# cyw20829 register map
Vendor: Infineon Technologies; Series: CYW20829; File version: 1.0
CPU: CM33 r0p1, little endian, MPU, no FPU, VTOR, 3 interrupt priority bits
Registers are 32-bit, read-write, reset 0x0 unless marked. A register's access mark holds for its fields unless they carry their own. Offsets are from the block's base; [hi:lo] are bit positions; {n}, {i} and the like mark numbered series.

## MXS40ADCMIC0 — ADC
Base 0x40520000
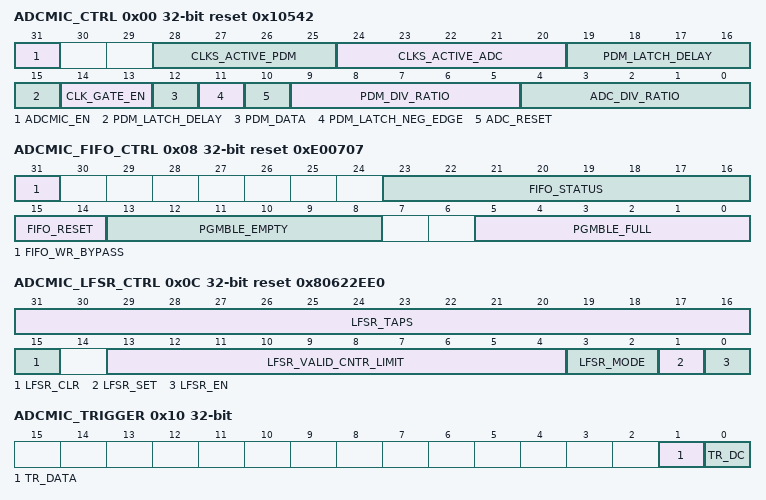
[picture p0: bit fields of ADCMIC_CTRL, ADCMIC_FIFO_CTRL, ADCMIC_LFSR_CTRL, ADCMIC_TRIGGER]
0x00 ADCMIC_CTRL reset 0x10542 — Control the operation of the ADCMIC block including clock generation,clock selection and pdm data latching
  [31] ADCMIC_EN — Enables the adcmic operation This bit controls the pdm data being latched to begin the adcmic operation.
  [28:25] CLKS_ACTIVE_PDM — clk sel for clk_pdm - one hot encoded but the lower 2 bits and the upper 2 bits are independent of each other 0000 : No clocks selected - clock is gated off XX01 : clk_pdm from local clk_divder is selected for external clk_pdm XX10 : Inverted clk_pdm from local clk_divder is selected for external clk_pdm 01XX : clk_pdm from local clk_divder is selected as internal clk_adc to process pdm_data 10XX : Inverted clk_pdm from local clk_divder is selected as internal clk_adc to latch pdm_data
  [24:20] CLKS_ACTIVE_ADC — clk sel for clk_adc - one hot encoded 00000 : No clocks selected - clock is gated off 00001 : clk_adc from local clk_divder is selected 00010 : Inverted clk_adc from local clk_divder is selected 00100 : clk_adc received from adc is used 01000 : Inverted clk_adc received from adc is used 10000 : clk_pdm_int is used as clk_adc
  [19:15] PDM_LATCH_DELAY — Number of clk_hf cycles from edge of clk_pdm to latch the pdm_data When pdm_latch_neg_edge is 0 valid values are 2 through 8 When pdm_latch_neg_edge is 1 valid values are 3 through 9
  [14:13] CLK_GATE_EN — Two bit clock gate control that enables the mxtk_clk_gate cells Bit 0: Controls clk_hf clock gate Bit 1: Controls the clk_adc_syn from the ADC block
  [12] PDM_DATA ro — pdm data synchronuzed to clkc_sys
  [11] PDM_LATCH_NEG_EDGE — Edge of clk_hf used to latch pdm_data 1: Latch on negative edge 0: Latch on positive edge
  [10] ADC_RESET — Reset for the adc domain 1: Out of reset and synchronized to clk_adc 0: In reset
  [9:5] PDM_DIV_RATIO — Divide ratio to divide clk_hf to generate clk_pdm to receive pdm_data
  [4:0] ADC_DIV_RATIO — Divide ratio to divide clk_hf to yield clk_adc to process pdm_data
0x04 ADCMIC_PAD_CTRL — Control the pads in the ADCMIC block
  [0] CLK_PDM_OE — Output enable for pdm clock
0x08 ADCMIC_FIFO_CTRL reset 0xE00707 — Controls the operation of the fifo
  [31] FIFO_WR_BYPASS — This is a bit set for debug where the data written into the fifo comes from the lfsr register
  [23:16] FIFO_STATUS ro — Indicates fifo status of the fifo that stores pcm data. The almost empty and almost full indicates there is 1 location before being full or empty and pgmble indicates the level is half the depth of the fifo that has a total depth of 64. A read of the fifo when empty will return 0 and will not read from the fifo so the underflow bit will never be set fifo_status[7] = afifo_empty fifo_status[6] = afifo_almost_empty fifo_status[5] = afifo_pgmble_empty fifo_status[4] = afifo_underflow fifo_status[3] = afifo_full fifo_status[2] = afifo_almost_full fifo_status[1] = afifo_pgmble_full fifo_status[0] = afifo_overflow
  [15:14] FIFO_RESET — [0] : fifo write reset when 0 and when 1 its out of reset [1] : fifo_read reset when 0 and when 1 its out of reset
  [13:8] PGMBLE_EMPTY — Number of programmable words to indicate distance to fifo_empty and will trigger programmable empty level (afifo_pgmble_empty)
  [5:0] PGMBLE_FULL — Number of programmable words to indicate distance to fifo_full and will trigger programmable full level (afifo_pgmble_full)
0x0C ADCMIC_LFSR_CTRL reset 0x80622EE0 — Controls the operation of the LFSR
  [31:16] LFSR_TAPS — This field provides the tap points for the LFSR wuth lfsr_taps[15:8] corresponds to tap points [31:24] of the lfsr register while lfsr_taps[7:0] corresponds to tap points [7:0] of the lfsr register.
  [15] LFSR_CLR — When this bit is 1 then the lfsr register resets to 32'h00000000
  [13:4] LFSR_VALID_CNTR_LIMIT — The valid pulse for the lfsr_data dictates validity on a cycle basis. By default there is a new pattern every 750(0x2EE) cycles
  [3:2] LFSR_MODE
  [1] LFSR_SET — When this bit is 1 then the lfsr register resets to 32'hFFFFFFFF
  [0] LFSR_EN — Write a 1 to this bit to begin the lfsr operation
0x10 ADCMIC_TRIGGER ro — Register to control Trigger
  [1] TR_DATA — Trigger when output fifo has valid data
  [0] TR_DC — Trigger when timer fires for DC measurement
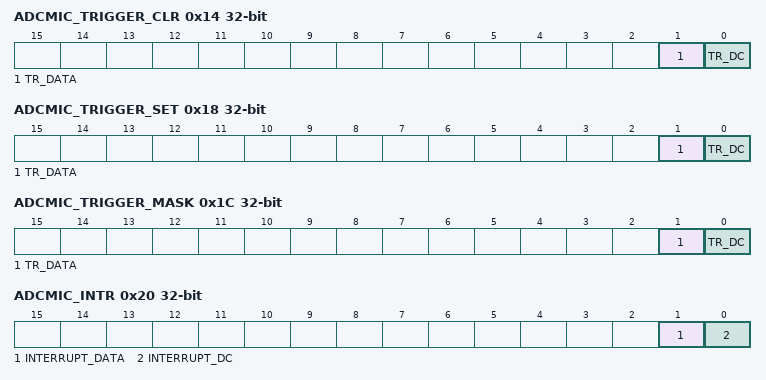
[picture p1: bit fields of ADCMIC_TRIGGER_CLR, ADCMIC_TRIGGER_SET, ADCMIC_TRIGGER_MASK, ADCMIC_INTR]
0x14 ADCMIC_TRIGGER_CLR — Register to clear Trigger
  [1] TR_DATA — Activate functionality: 0: No effect. 1: Bit is set to 0.
  [0] TR_DC — Activate functionality: 0: No effect. 1: Bit is set to 0.
0x18 ADCMIC_TRIGGER_SET — Register to set Trigger
  [1] TR_DATA — Activate functionality: 0: No effect. 1: Bit is set to 1.
  [0] TR_DC — Activate functionality: 0: No effect. 1: Bit is set to 1.
0x1C ADCMIC_TRIGGER_MASK — Register to mask Trigger
  [1] TR_DATA — Mask for corresponding field in ADCMIC_TRIGGER register.
  [0] TR_DC — Mask for corresponding field in ADCMIC_TRIGGER register.
0x20 ADCMIC_INTR — Register to cause Interrupt
  [1] INTERRUPT_DATA — HW sets this field to 1, when fifo has valid data
  [0] INTERRUPT_DC — HW sets this field to 1, when dc measurement is done.
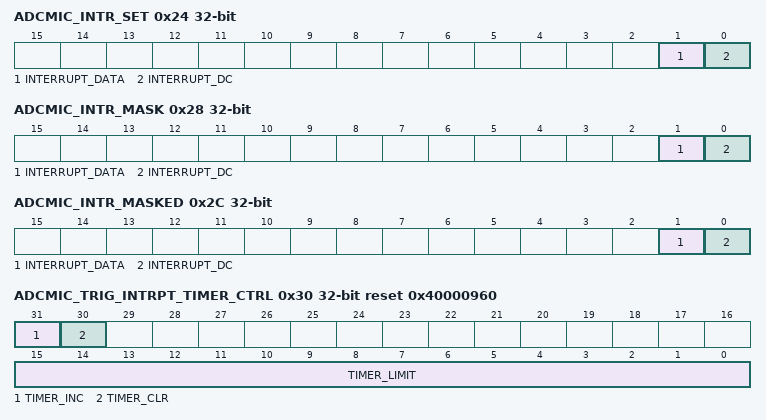
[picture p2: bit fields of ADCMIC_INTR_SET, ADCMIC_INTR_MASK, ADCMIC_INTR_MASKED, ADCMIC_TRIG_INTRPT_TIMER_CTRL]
0x24 ADCMIC_INTR_SET — Register to set Interrupt
  [1] INTERRUPT_DATA — Write this field with '1' to set corresponding ADCMIC_INTR field (a write of '0' has no effect).
  [0] INTERRUPT_DC — Write this field with '1' to set corresponding ADCMIC_INTR field (a write of '0' has no effect).
0x28 ADCMIC_INTR_MASK — Register to mask Interrupt
  [1] INTERRUPT_DATA — Mask for corresponding field in ADCMIC_INTR register.
  [0] INTERRUPT_DC — Mask for corresponding field in ADCMIC_INTR register.
0x2C ADCMIC_INTR_MASKED ro — Register to and intr_mask Intr to crreate the interrupt
  [1] INTERRUPT_DATA — Logical AND of corresponding ADCMIC_INTR and ADCMIC_INTR_MASK fields.
  [0] INTERRUPT_DC — Logical AND of corresponding ADCMIC_INTR and ADCMIC_INTR_MASK fields.
0x30 ADCMIC_TRIG_INTRPT_TIMER_CTRL reset 0x40000960 — Controls the timer for the generation of triggers and interrupts for dc measurement in the block
  [31] TIMER_INC — Enable the timer to begin counting on every clk_sys cycle to timer_limit and then generate the interrupt. 1: Counts up every clk_sys cycle 0: Counts when cic is updated
  [30] TIMER_CLR — When high clk_timer is cleared
  [15:0] TIMER_LIMIT — At 96Mhz this count will generate interrupt to indicate that 25us has lapsed and the ADC core digital voltage is valid.
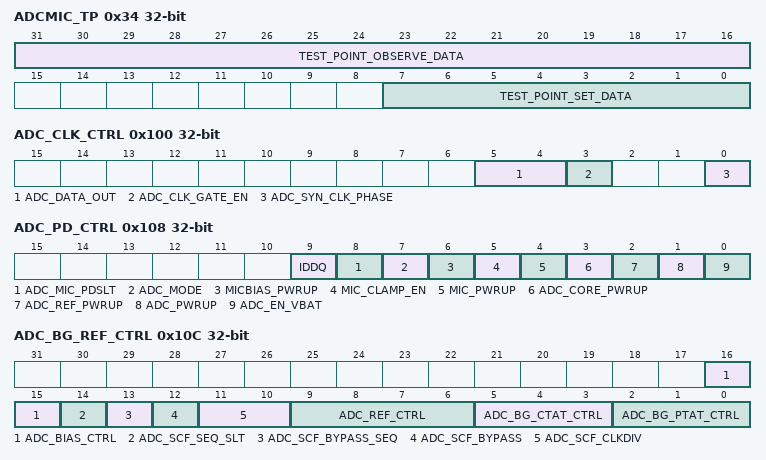
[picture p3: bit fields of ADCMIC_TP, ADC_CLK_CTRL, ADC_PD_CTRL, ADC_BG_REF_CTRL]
0x34 ADCMIC_TP — Data used for DFT test for setting and observing test points
  [31:16] TEST_POINT_OBSERVE_DATA ro — Bits to observe tests points
  [7:0] TEST_POINT_SET_DATA — Bits to control tests points
0x40 ADCMIC_DATA ro
  [31:0] FIFO_DATA — Data from the FIFO which contains two pcm data samples of 16 bits with the first sample in the lower half and the next sample in the upper half
0x100 ADC_CLK_CTRL — Control the clocks in the ADC block
  [5:4] ADC_DATA_OUT ro — Two bit PDM data from ADC that is latched 3-level ADC data outputs: 11 High 01 Mid 00 Low
  [3] ADC_CLK_GATE_EN — Clock gate control to enable the clock to ADC 0: Clock is Disabled 1: Clock is Enabled
  [0] ADC_SYN_CLK_PHASE — Output synchronization clock phase control 0: non-inverted clock phase 1: inverted clock phase
0x104 ADC_GPIO_CTRL — GPIO control for ADC
  [4:0] ADC_DCIN_MUX — ADC DC input selection (32-to-1 MUX) but only the lower 8 GPIO's are enabled so the selection is limited to GPIO 0 through 7: 01111 ADC reference ground (ADC_REFGND) 01110 ADC BG REF (ADC_BGREF) 01101 Core supply (VDDC) 01100 Battery/IO supply (VBAT/VDDIO) 01011 GPIO 27 01010 GPIO 26 01001 GPIO 25 01000 GPIO 24 00111 GPIO 23 00110 GPIO 22 00101 GPIO 21 00100 GPIO 20 00011 GPIO 19 00010 GPIO 18 00001 GPIO 17 00000 GPIO 16 11111 GPIO 15 11110 GPIO 14 11101 GPIO 13 11100 GPIO 12 11011 GPIO 11 11010 GPIO 10 11001 GPIO 9 11000 GPIO 8 10111 GPIO 7 10110 GPIO 6 10101 GPIO 5 10100 GPIO 4 10011 GPIO 3 10010 GPIO 2 10001 GPIO 1 10000 GPIO 0
0x108 ADC_PD_CTRL — Control the power down controls in the ADC block.
  [9] IDDQ — Chip global power down control: 0: power up (Default) 1: power down
  [8] ADC_MIC_PDSLT — MIC path power up/down control selection in DC measurement mode: 0: Power down MIC Bias and PGA in DC measurement Mode 1: MIC path power up/down controlled by its pwrdn signal
  [7] ADC_MODE — MIC (Audio) input and DC measurement input selection: 0 ADC in DC Measurement Mode; DC measurement path enabled; MIC path powered down 1 ADC in Audio application Mode; MIC path enabled. DC input is gated
  [6] MICBIAS_PWRUP — MIC bias power up/down: 0: power down MIC Bias(Default) 1: Power up
  [5] MIC_CLAMP_EN — MIC PGA clamping enable/disable: 0: disable MIC PGA clamping (Default) 1: enable MIC PGA clamping
  [4] MIC_PWRUP — ADC MIC (Audio) path power up/down control: 0: power down MIC bias and PGA (Default) 1: power up
  [3] ADC_CORE_PWRUP — ADC core power up/down: 0: power down ADC Core (Default) 1: power up
  [2] ADC_REF_PWRUP — ADC BG & REF power up/down: 0: power down BG and REF (Default) 1: power up
  [1] ADC_PWRUP — ADC IP level main power up/down control: 0: power down whole ADC IP (Default) 1: power up
  [0] ADC_EN_VBAT — ADC IP level enable control from avddBAT supply domain: 0: power down all the blocks supplied by VBAT when the core supply is not ready 1: ADC power up/down controlled by 1.2V power up/down signals Enable control signal in 1.6V-3.6V avddBAT supply domain
0x10C ADC_BG_REF_CTRL — Control the Band Gap and Reference Voltages of the ADC
  [16:15] ADC_BIAS_CTRL — Global bias current programmability 10: 3.0uA 11: 2.5uA 00: 2.5uA 01: 2.0uA
  [14] ADC_SCF_SEQ_SLT — Internal/External BG SCF power up sequence selection: 0: use internal power up sequence 1: use external power up sequence
  [13] ADC_SCF_BYPASS_SEQ — External power up sequence for BG SCF bypass
  [12] ADC_SCF_BYPASS — BG REF switch cap filter bypass 0: enable switch cap filter 1: bypass switch cap filter
  [11:10] ADC_SCF_CLKDIV — Switch cap filter clock frequency selection: 00: 50KHz (default) 01: 25KHz 10: 100KHz 11: 1.6MHz
  [9:6] ADC_REF_CTRL — ADC reference voltage programmability: [3:0] Vref(mV) 0000 850.0 0001 856.1 0010 862.1 0011 868.2 0100 874.3 0101 880.4 0110 886.4 0111 892.5 1000 801.4 1001 807.5 1010 813.6 1011 819.6 1100 825.7 1101 831.8 1110 837.9 1111 843.9
  [5:3] ADC_BG_CTAT_CTRL — BG CTAT current adjustment: 011 3.02 percent 010 1.92 percent 001 0.92 percent 000 0.00 percent 111 -0.93 percent 110 -1.82 percent 101 -2.68 percent 100 -3.51 percent
  [2:0] ADC_BG_PTAT_CTRL — BG PTAT current adjustment: 011 3.62 percent 010 2.32 percent 001 1.11 percent 000 0.00 percent 111 -1.11 percent 110 -2.17 percent 101 -3.19 percent 100 -4.10 percent
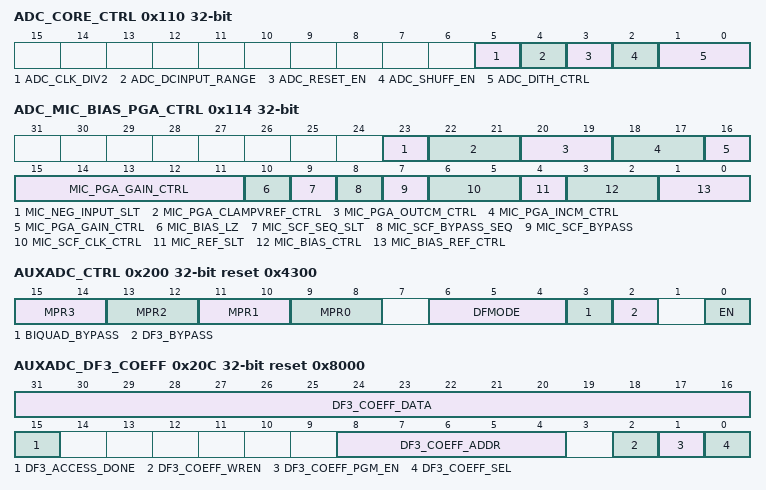
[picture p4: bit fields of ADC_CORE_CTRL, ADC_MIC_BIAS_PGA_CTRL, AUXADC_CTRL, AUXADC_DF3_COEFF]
0x110 ADC_CORE_CTRL — Control the clocks in the ADC block
  [5] ADC_CLK_DIV2 — ADC internal clock division: 0: disable divide-by-2; ADC sampling clock at 12MHz 1: enable divide-by-2; ADC sampling clock at 6MHz
  [4] ADC_DCINPUT_RANGE — ADC input range selection for DC measurement path: 0: 0-3.6V 1: 0-1.8V
  [3] ADC_RESET_EN — Disable reset function in DC measurement: 0: disabled 1: enabled
  [2] ADC_SHUFF_EN — Disable the shuffler: 0: disabled 1: enabled
  [1:0] ADC_DITH_CTRL — Dither Sequence control 00: No dither 01: prbs15 10: prbs23 11: prbs31
0x114 ADC_MIC_BIAS_PGA_CTRL — Control the BIAS and PGA of ADC block
  [23] MIC_NEG_INPUT_SLT
  [22:21] MIC_PGA_CLAMPVREF_CTRL — PGA clamp threshold voltage control 01 : 0.92 V 00 : 0.95 V 10 : 0.975 V 11 : 1 V
  [20:19] MIC_PGA_OUTCM_CTRL — PGA output common mode control 01 : 0.7 00 : 0.6 10 : 0.5
  [18:17] MIC_PGA_INCM_CTRL — PGA input common mode control 01 : 0.45 * avdd 00 : 0.4 * avdd 10 : 0.35 * avdd
  [16:11] MIC_PGA_GAIN_CTRL — MIC PGA gain control: 1dB steps 000000 : 0 dB 000001 : 1 dB 000010 : 2 dB 000011 : 3 dB 000100 : 4 dB 000101 : 5 dB 000110 : 6 dB 000111 : 7 dB 001000 : 8 dB 001001 : 9 dB 001010 : 10 dB 001011 : 11 dB 001100 : 12 dB 001101 : 13 dB 001110 : 14 dB 001111 : 15 dB 010000 : 16 dB 010001 : 17 dB 010010 : 18 dB 010011 : 19 dB 010100 : 20 dB 010101 : 21 dB 010110 : 22 dB 010111 : 23 dB 011000 : 24 dB 011001 : 25 dB 011010 : 26 dB 011011 : 27 dB 011100 : 28 dB 011101 : 29 dB 011110 : 30 dB 011111 : 31 dB 100000 : 32 dB 100001 : 33 dB 100010 : 34 dB 100011 : 35 dB 100100 : 36 dB 100101 : 37 dB 100110 : 38 dB 100111 : 39 dB 101000 : 40 dB 101001 : 41 dB 101010 : 42 dB
  [10] MIC_BIAS_LZ — MIC bias low/high output impedance control during power down mode: 0: MIC bias output is HZ in power down mode (default) 1: MIC bias output is LZ in power down mode
  [9] MIC_SCF_SEQ_SLT — Internal/External MIC bias SCF power up sequence selection: 0: use internal power up sequence 1: use external power up sequence
  [8] MIC_SCF_BYPASS_SEQ — External power up sequence for MIC bias SCF bypass
  [7] MIC_SCF_BYPASS — MIC bias switch cap filter bypass 0: enable switch cap filter 1: bypass switch cap filter
  [6:5] MIC_SCF_CLK_CTRL — MIC bias reference filter clock programmability: 00: 50KHz (default) 01: 25KHz 10: 100KHz 11: 1.6MHz
  [4] MIC_REF_SLT — MIC bias reference selection: 0: supply as MIC bias reference. MIC bias output voltage scaled with supply voltage 1: BG voltage as MIC bias reference to have constant MIC bias output voltage
  [3:2] MIC_BIAS_CTRL — MIC bias output voltage programmability: 00: 1.12 X Reference Voltage (default) 01: 1.14 X Reference voltage 10: 1.17 X Reference voltage 11: 1.10 X Reference voltage
  [1:0] MIC_BIAS_REF_CTRL — MIC bias reference voltage programmability: 00: 75 percent of Audio Supply (default) 10: 80 percent of Audio Supply 01 / 11: 70 percent of Audio Supply
0x118 ADC_SPARE — Spare registers in the ADC block
  [9:0] ADC_SPARE — Spare Bits adc_spare[7] External reset of ADC 0: Disabled 1: Enabled
0x200 AUXADC_CTRL reset 0x4300 — Register to control AuxAdcDecim operation
  [15:14] MPR3 — Mapping bits mpr3 that maps to ADC data 11 or PDM data 1
  [13:12] MPR2 — Mapping bits mpr2 that maps to ADC data 10
  [11:10] MPR1 — Mapping bits mpr1 that maps to ADC data 01
  [9:8] MPR0 — Mapping bits mpr0 that maps to ADC data 00 or PDM data 0
  [6:4] DFMODE — Mode of Operation 0 : DC mode, 480kHz, fast: with DC convergence time of 10^-6 seconds 1 : DC mode, 480kHz, medium: with DC convergence time of 15^-6 seconds 2 : DC mode, 480kHz, slow: with DC convergence time of 20^-6 seconds 3 : Audio mode, 16kHz, analog mic 4 : Audio mode, 16kHz, digital mic 5 : Audio mode, 8kHz, analog mic 6 : Audio mode, 8kHz, digital mic
  [3] BIQUAD_BYPASS — When 1 bypass biquad completely else biquad is enabled
  [2] DF3_BYPASS — When 1 bypass df3 FIR completely else FIR is enabled
  [0] EN — When 1 enable the aux_adc block
0x204 AUXADC_CIC_CTRL — Register to control CIC operation in AuxAdcDecim block
  [15:0] CIC_GAIN — CIC gain value that will be used only during override. This will be used only when AUXADC_OVERRIDE[22] is set
0x208 AUXADC_OVERRIDE — Register that holds the override values for AuxAdcDecim block
  [22:0] OVERRIDE — Override Values for Auxadc. When override[22] is set then the remaining buts will override the default values within the matlab model generated RTL code Bit 22 When set the values below are used to configure the auxAdcDecim block otherwise it defaults to the default values within the matlab generated code The cic gain is picked from the AUXADC_CIC_CTRL register when this is set. In the matlab model this is based on dfmode as follows: dfmode 000 : 16'h68DC dfmode 001 : 16'h8638 dfmode 010 : 16'h2CBD dfmode 011 : 16'hD1B7 dfmode 100 : 16'h51EC dfmode 101 : 16'h346E dfmode default : 16'hA3D7 Bits 21:16 Sets up counters for various modes of operation - In the matlab model this is based on dfmode as follows: dfmode 000 : 6'b000100 dfmode 001 : 6'b000100 dfmode 010 : 6'b000100 dfmode 011 : 6'b000100 dfmode 100 : 6'b000100 dfmode 101 : 6'b001001 dfmode default : 6'b001001 Bits 15:13 Sets up counters for CIC integrator to sample input - is a constant 3'b100 in the matlab model and is used when pdm is not enabled Bits 12:10 The gain in the CIC integrator. In the matlab model this is based on dfmode as follows: dfmode 000 : 3'b011 dfmode 001 : 3'b101 dfmode 010 : 3'b101 dfmode 011 : 3'b011 dfmode 100 : 3'b001 dfmode 101 : 3'b011 dfmode default : 3'b010 Bits 09 Used for enabling pdm mode. In the matlab model this is set to 1 if dfmode is 4 or 6 and is the select of a mux that selects the pulse to sample pdm data. Bits 08 This bit when set bypasses the 3rd stage of the integration in CIC. In the matlab model this is based on dfmode as follows: dfmode 000 : 1'b1 dfmode 001 : 1'b0 dfmode 010 : 1'b0 dfmode 011 : 1'b1 dfmode 100 : 1'b1 dfmode 101 : 1'b1 dfmode default : 1'b1 Bits 07:06 The delay in the first stage of CIC differntiator. In the matlab model this is based on dfmode as follows: dfmode 000 : 2'b01 dfmode 001 : 2'b01 dfmode 010 : 2'b11 dfmode 011 : 2'b00 dfmode 100 : 2'b00 dfmode 101 : 2'b00 dfmode default : 2'b00 Bits 05:04 The delay in the second stage of CIC differntiator. In the matlab model this is based on dfmode as follows: dfmode 000 : 2'b00 dfmode 001 : 2'b01 dfmode 010 : 2'b10 dfmode 011 : 2'b00 dfmode 100 : 2'b00 dfmode 101 : 2'b00 dfmode default : 2'b00 Bits 03 The delay in the third stage of CIC differntiator. In the matlab model this is constant 0 irrespective of dfmode Bits 02:0 Enables various filters in the design. If the value is >=1 then df1 is enabled if >=2 then df2 is enabled if >=3 then df3 is enabled if >=4 then biquad is enabled. In the matlab model this is based on dfmode as follows: dfmode 000 : 3'b000 dfmode 001 : 3'b000 dfmode 010 : 3'b000 dfmode 011 : 3'b100 dfmode 100 : 3'b100 dfmode 101 : 3'b100 dfmode default : 3'b100
0x20C AUXADC_DF3_COEFF reset 0x8000 — Register that controls the RAM operation for writing DF3 Coefficients into the RAM
  [31:16] DF3_COEFF_DATA — Data for writing Coefficient of df3 during the write cycle and read data during the read cycle
  [15] DF3_ACCESS_DONE — Hardware sets this bit when the operation is done while software clears this bit to start operation
  [8:4] DF3_COEFF_ADDR — Address for writing Coefficient of df3
  [2] DF3_COEFF_WREN — Write Enable for writing Coefficient of df3
  [1] DF3_COEFF_PGM_EN — Enable this bit before the df3_coeff ram can be programmed
  [0] DF3_COEFF_SEL — Sel for selecting Coefficient of df3 from the ram during the filtering at this stage
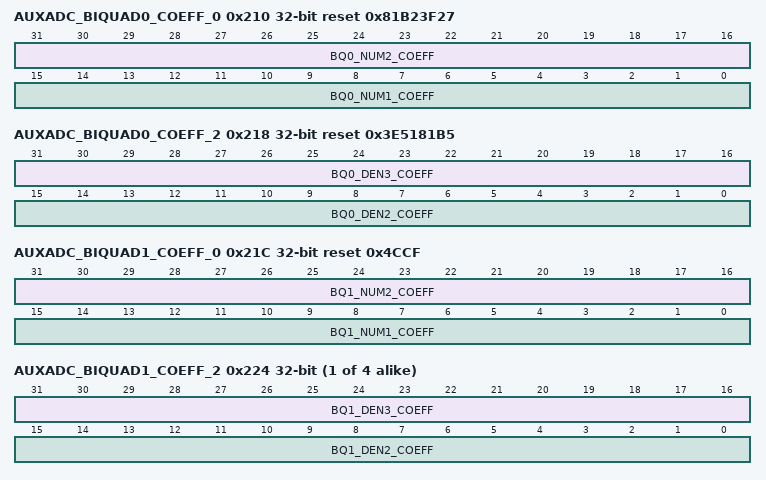
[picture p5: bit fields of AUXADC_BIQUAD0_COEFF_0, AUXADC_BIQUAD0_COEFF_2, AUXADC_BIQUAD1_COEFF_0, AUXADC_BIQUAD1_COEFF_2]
0x210 AUXADC_BIQUAD0_COEFF_0 reset 0x81B23F27 — Register holding the coefficients for BIQUAD0 operation.
  [31:16] BQ0_NUM2_COEFF — Coefficient for biquad0_num2
  [15:0] BQ0_NUM1_COEFF — Coefficient for biquad0_num1
0x214 AUXADC_BIQUAD0_COEFF_1 reset 0x3F27 — Register holding the coefficients for BIQUAD0 operation.
  [15:0] BQ0_NUM3_COEFF — Coefficient for biquad0_num1
0x218 AUXADC_BIQUAD0_COEFF_2 reset 0x3E5181B5 — Register holding the coefficients for BIQUAD0 operation.
  [31:16] BQ0_DEN3_COEFF — Coefficient for biquad0_num2
  [15:0] BQ0_DEN2_COEFF — Coefficient for biquad0_num1
0x21C AUXADC_BIQUAD1_COEFF_0 reset 0x4CCF — Register holding the coefficients for BIQUAD1 operation.
  [31:16] BQ1_NUM2_COEFF — Coefficient for biquad1_num2
  [15:0] BQ1_NUM1_COEFF — Coefficient for biquad1_num1
0x220 AUXADC_BIQUAD1_COEFF_1 — Register holding the coefficients for BIQUAD1 operation.
  [15:0] BQ1_NUM3_COEFF — Coefficient for biquad1_num1
{0x218+0xC*i} AUXADC_BIQUAD{i}_COEFF_2 (i=1..4) — Register holding the coefficients for BIQUAD{i} operation.
  [31:16] BQ{i}_DEN3_COEFF — Coefficient for biquad{i}_num2
  [15:0] BQ{i}_DEN2_COEFF — Coefficient for biquad{i}_num1
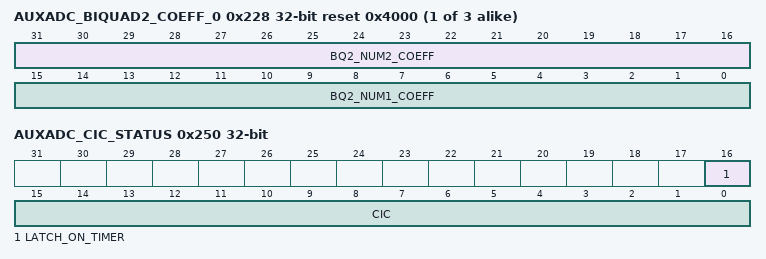
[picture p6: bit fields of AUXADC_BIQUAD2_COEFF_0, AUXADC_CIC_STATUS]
{0x210+0xC*i} AUXADC_BIQUAD{i}_COEFF_0 reset 0x4000 (i=2..4) — Register holding the coefficients for BIQUAD{i} operation.
  [31:16] BQ{i}_NUM2_COEFF — Coefficient for biquad{i}_num2
  [15:0] BQ{i}_NUM1_COEFF — Coefficient for biquad{i}_num1
0x22C AUXADC_BIQUAD2_COEFF_1 — Register holding the coefficients for BIQUAD2 operation.
  [15:0] BQ2_NUM3_COEFF — Coefficient for biquad2_num1
0x238 AUXADC_BIQUAD3_COEFF_1 — Register holding the coefficients for BIQUAD3 operation.
  [15:0] BQ3_NUM3_COEFF — 'Coefficient for biquad3_num1
0x244 AUXADC_BIQUAD4_COEFF_1 — Register holding the coefficients for BIQUAD4 operation.
  [15:0] BQ4_NUM3_COEFF — Coefficient for biquad4_num1
0x250 AUXADC_CIC_STATUS (reset mask 0x10000) — Status of the CIC in AuxAdcDecim block
  [16] LATCH_ON_TIMER — Latches continously by default but when set to 1 it latches on timer
  [15:0] CIC ro — Computed cic value
{0x250+4i} AUXADC_DF{i}_STATUS ro reset not defined (i=1..3) — Status of the DF{i} FIR Filter in AuxAdcDecim block
  [15:0] DF{i} — Computed df{i} value
0x260 AUXADC_BIQUAD_STATUS ro reset not defined — Status of the BIQUAD IIR Filter in AuxAdcDecim block
  [15:0] BQ — Computed bq value
